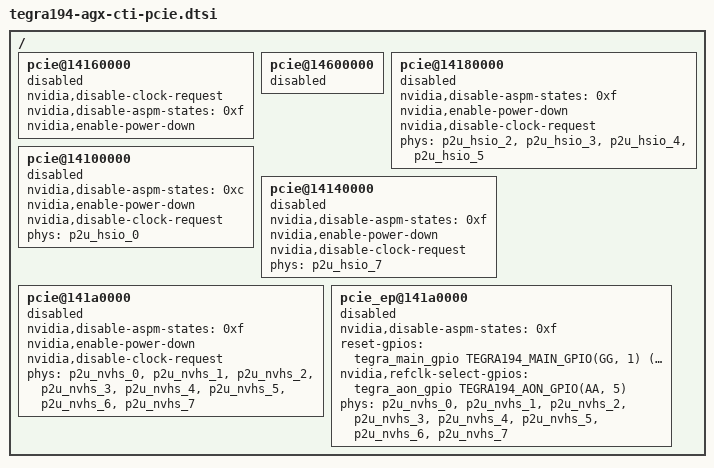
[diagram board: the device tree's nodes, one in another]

/ {

	pcie@14160000 {
        status = "disabled";

        nvidia,disable-clock-request;
        nvidia,disable-aspm-states = <0xf>;
        nvidia,enable-power-down;
		

    };
	
    pcie@14600000 {
        status = "disabled";
    };

    pcie@14180000 {
        status = "disabled";

        nvidia,disable-aspm-states = <0xf>;
        nvidia,enable-power-down;
        nvidia,disable-clock-request;

        phys = <&p2u_hsio_2>, <&p2u_hsio_3>, <&p2u_hsio_4>,
               <&p2u_hsio_5>;
        phy-names = "p2u-0", "p2u-1", "p2u-2", "p2u-3";
    };

    pcie@14100000 {
        status = "disabled";

        nvidia,disable-aspm-states = <0xc>;
        nvidia,enable-power-down;
        nvidia,disable-clock-request;

        phys = <&p2u_hsio_0>;
        phy-names = "p2u-0";
    };

    pcie@14140000 {
        status = "disabled";

        nvidia,disable-aspm-states = <0xf>;
        nvidia,enable-power-down;
        nvidia,disable-clock-request;

        phys = <&p2u_hsio_7>;
        phy-names = "p2u-0";
    };

    pcie@141a0000 {
        status = "disabled";

        nvidia,disable-aspm-states = <0xf>;
        nvidia,enable-power-down;
        nvidia,disable-clock-request;

        phys = <&p2u_nvhs_0>, <&p2u_nvhs_1>, <&p2u_nvhs_2>,
               <&p2u_nvhs_3>, <&p2u_nvhs_4>, <&p2u_nvhs_5>,
               <&p2u_nvhs_6>, <&p2u_nvhs_7>;

        phy-names = "p2u-0", "p2u-1", "p2u-2", "p2u-3", "p2u-4",
                    "p2u-5", "p2u-6", "p2u-7";
    };

    pcie_ep@141a0000 {
        status = "disabled";

        nvidia,disable-aspm-states = <0xf>;

        reset-gpios = <&tegra_main_gpio TEGRA194_MAIN_GPIO(GG, 1) GPIO_ACTIVE_LOW>;

        nvidia,refclk-select-gpios = <&tegra_aon_gpio TEGRA194_AON_GPIO(AA, 5)
                          GPIO_ACTIVE_HIGH>;

        phys = <&p2u_nvhs_0>, <&p2u_nvhs_1>, <&p2u_nvhs_2>,
               <&p2u_nvhs_3>, <&p2u_nvhs_4>, <&p2u_nvhs_5>,
               <&p2u_nvhs_6>, <&p2u_nvhs_7>;

        phy-names = "p2u-0", "p2u-1", "p2u-2", "p2u-3", "p2u-4",
                    "p2u-5", "p2u-6", "p2u-7";
    };
};
